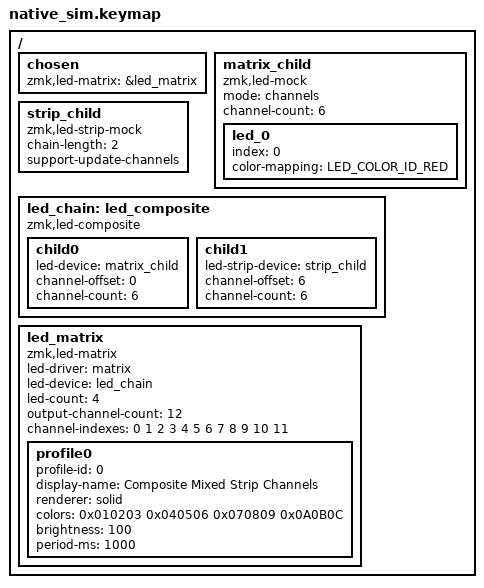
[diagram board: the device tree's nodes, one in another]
#include "../behavior_keymap.dtsi"

/ {
    chosen {
        zmk,led-matrix = &led_matrix;
    };

    matrix_child: matrix_child {
        compatible = "zmk,led-mock";
        mode = "channels";
        channel-count = <6>;

        led_0 {
            index = <0>;
            color-mapping = <LED_COLOR_ID_RED>;
        };
    };

    strip_child: strip_child {
        compatible = "zmk,led-strip-mock";
        chain-length = <2>;
        support-update-channels;
    };

    led_chain: led_composite {
        compatible = "zmk,led-composite";

        child0 {
            led-device = <&matrix_child>;
            channel-offset = <0>;
            channel-count = <6>;
        };

        child1 {
            led-strip-device = <&strip_child>;
            channel-offset = <6>;
            channel-count = <6>;
        };
    };

    led_matrix: led_matrix {
        compatible = "zmk,led-matrix";
        led-driver = "matrix";
        led-device = <&led_chain>;
        led-count = <4>;
        output-channel-count = <12>;
        channel-indexes = <
            0 1 2
            3 4 5
            6 7 8
            9 10 11
        >;

        profile0 {
            profile-id = <0>;
            display-name = "Composite Mixed Strip Channels";
            renderer = "solid";
            colors = <0x010203 0x040506 0x070809 0x0A0B0C>;
            brightness = <100>;
            period-ms = <1000>;
        };
    };
};
